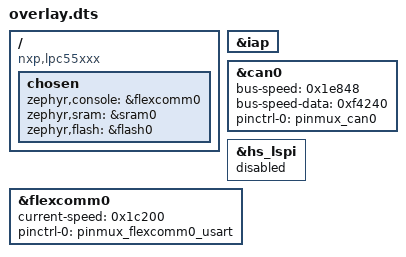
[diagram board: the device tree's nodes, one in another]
/ {
	compatible = "nxp,lpc55xxx", "nxp,lpc";
	chosen {
		zephyr,console = &flexcomm0;
		zephyr,sram = &sram0;
		zephyr,flash = &flash0;
	};
};
&iap{
	status = "okay";
};
&can0{
	status = "okay";
	bus-speed = < 0x1e848 >;
	bus-speed-data = < 0xf4240 >;
	pinctrl-0 = < &pinmux_can0 >;
	pinctrl-names = "default";
};
&hs_lspi{
	status = "disabled";
};
&flexcomm0{
	status = "okay";
	current-speed = < 0x1c200 >;
	pinctrl-0 = < &pinmux_flexcomm0_usart >;
	pinctrl-names = "default";
};
